# ESP32-H2 register map
Vendor: ESPRESSIF SYSTEMS (SHANGHAI) CO., LTD.; Series: ESP32 H-Series; File version: 12
CPU: RV32IMAC r0p0, little endian, no MPU, no FPU, 0 interrupt priority bits
Address unit: 32 bits
Registers are 32-bit, read-write, reset 0x0 unless marked. A register's access mark holds for its fields unless they carry their own. Offsets are from the block's base; [hi:lo] are bit positions; {n}, {i} and the like mark numbered series.

## HP_APM — HP_APM Peripheral
Base 0x60099000
0x00 REGION_FILTER_EN reset 0x1 — Region filter enable register
  [15:0] REGION_FILTER_EN — Region filter enable
{0x4+0xC*i} REGION{i}_ADDR_START (i=0..15) — Region address register
  [31:0] REGION{i}_ADDR_START — Start address of region{i}
{0x8+0xC*i} REGION{i}_ADDR_END reset 0xFFFFFFFF (i=0..15) — Region address register
  [31:0] REGION{i}_ADDR_END — End address of region{i}
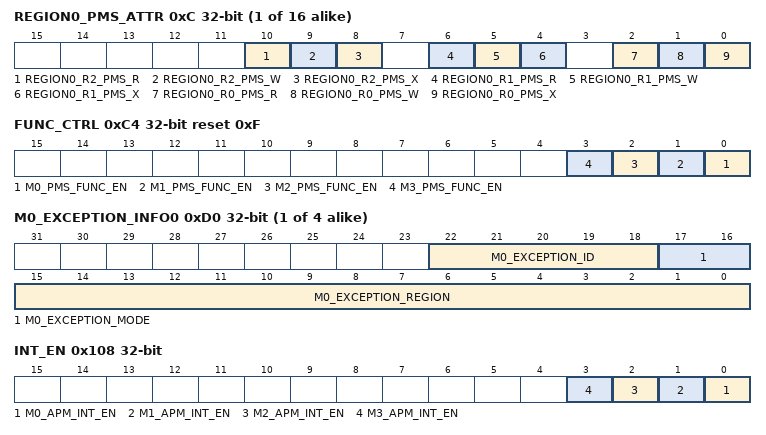
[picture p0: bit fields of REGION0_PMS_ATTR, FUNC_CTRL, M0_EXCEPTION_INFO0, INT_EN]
{0xC+0xC*i} REGION{i}_PMS_ATTR (i=0..15) — Region access authority attribute register
  [10] REGION{i}_R2_PMS_R — Region read authority in REE_MODE2
  [9] REGION{i}_R2_PMS_W — Region write authority in REE_MODE2
  [8] REGION{i}_R2_PMS_X — Region execute authority in REE_MODE2
  [6] REGION{i}_R1_PMS_R — Region read authority in REE_MODE1
  [5] REGION{i}_R1_PMS_W — Region write authority in REE_MODE1
  [4] REGION{i}_R1_PMS_X — Region execute authority in REE_MODE1
  [2] REGION{i}_R0_PMS_R — Region read authority in REE_MODE0
  [1] REGION{i}_R0_PMS_W — Region write authority in REE_MODE0
  [0] REGION{i}_R0_PMS_X — Region execute authority in REE_MODE0
0xC4 FUNC_CTRL reset 0xF — PMS function control register
  [n] M{n}_PMS_FUNC_EN (n=0..3) — PMS M{n} function enable
{0xC8+0x10*i} M{i}_STATUS ro (i=0..3)
  [1:0] M{i}_EXCEPTION_STATUS — Exception status
{0xCC+0x10*i} M{i}_STATUS_CLR wo (i=0..3) — M{i} status clear register
  [0] M{i}_REGION_STATUS_CLR — Clear exception status
{0xD0+0x10*i} M{i}_EXCEPTION_INFO0 ro (i=0..3)
  [22:18] M{i}_EXCEPTION_ID — Exception id information
  [17:16] M{i}_EXCEPTION_MODE — Exception mode
  [15:0] M{i}_EXCEPTION_REGION — Exception region
{0xD4+0x10*i} M{i}_EXCEPTION_INFO1 ro (i=0..3)
  [31:0] M{i}_EXCEPTION_ADDR — Exception addr
0x108 INT_EN — APM interrupt enable register
  [n] M{n}_APM_INT_EN (n=0..3) — APM M{n} interrupt enable
0x10C CLOCK_GATE reset 0x1 — clock gating register
  [0] CLK_EN — reg_clk_en
0x7FC DATE reset 0x2205240 — Version register
  [27:0] DATE — reg_date

## INTPRI — INTPRI Peripheral
Base 0x600C5000
0x00 CPU_INT_ENABLE — register description
  [31:0] CPU_INT_ENABLE — Need add description
0x04 CPU_INT_TYPE — register description
  [31:0] CPU_INT_TYPE — Need add description
0x08 CPU_INT_EIP_STATUS ro — register description
  [31:0] CPU_INT_EIP_STATUS — Need add description
{0xC+4i} CPU_INT_PRI_{i} (i=0..31) — register description
  [3:0] CPU_PRI_{i}_MAP — Need add description
0x8C CPU_INT_THRESH — register description
  [7:0] CPU_INT_THRESH — Need add description
{0x90+4i} CPU_INTR_FROM_CPU_{i} (i=0..3) — register description
  [0] CPU_INTR_FROM_CPU_{i} — Need add description
0xA0 DATE reset 0x2201090 — register description
  [27:0] DATE — Need add description
0xA4 CLOCK_GATE reset 0x1 — register description
  [0] CLK_EN — Need add description
0xA8 CPU_INT_CLEAR — register description
  [31:0] CPU_INT_CLEAR — Need add description
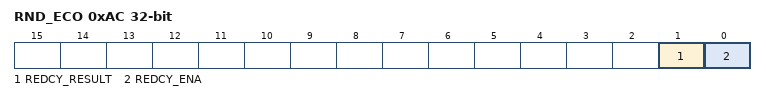
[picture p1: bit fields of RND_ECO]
0xAC RND_ECO access per field — redcy eco register.
  [1] REDCY_RESULT ro — Only reserved for ECO.
  [0] REDCY_ENA rw — Only reserved for ECO.
0xB0 RND_ECO_LOW — redcy eco low register.
  [31:0] REDCY_LOW — Only reserved for ECO.
0x3FC RND_ECO_HIGH reset 0xFFFFFFFF — redcy eco high register.
  [31:0] REDCY_HIGH — Only reserved for ECO.

## IO_MUX — Input/Output Multiplexer
Base 0x60090000
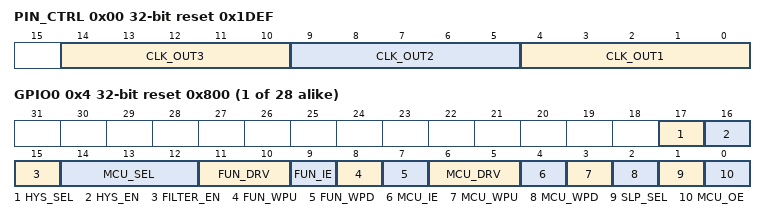
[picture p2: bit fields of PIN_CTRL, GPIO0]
0x00 PIN_CTRL reset 0x1DEF — Clock Output Configuration Register
  [14:10] CLK_OUT3 — If you want to output clock for I2S to CLK_OUT_out3, set this register to 0x0. CLK_OUT_out3 can be found in peripheral output signals.
  [9:5] CLK_OUT2 — If you want to output clock for I2S to CLK_OUT_out2, set this register to 0x0. CLK_OUT_out2 can be found in peripheral output signals.
  [4:0] CLK_OUT1 — If you want to output clock for I2S to CLK_OUT_out1, set this register to 0x0. CLK_OUT_out1 can be found in peripheral output signals.
{0x4+4i} GPIO{i} (i=0..27) reset 0x800 — IO MUX Configure Register for pad GPIO0
  [17] HYS_SEL — Select enabling signals of the pad from software and efuse hardware. 1: Select enabling siganl from slftware. 0: Select enabling signal from efuse hardware.
  [16] HYS_EN — Software enables hysteresis function for the pad. 1: Hysteresis enabled. 0: Hysteresis disabled.
  [15] FILTER_EN — Enable filter for pin input signals. 1: Filter enabled. 0: Filter disabled.
  [14:12] MCU_SEL — Select IO MUX function for this signal. 0: Select Function 1. 1: Select Function 2. etc.
  [11:10] FUN_DRV — Select the drive strength of the pad. 0: ~5 mA. 1: ~10mA. 2: ~20mA. 3: ~40mA.
  [9] FUN_IE — Input enable of the pad. 1: input enabled. 0: input disabled.
  [8] FUN_WPU — Pull-up enable of the pad. 1: internal pull-up enabled. 0: internal pull-up disabled.
  [7] FUN_WPD — Pull-down enable of the pad. 1: internal pull-down enabled. 0: internal pull-down disabled.
  [6:5] MCU_DRV — Select the drive strength of the pad during sleep mode. 0: ~5 mA. 1: ~10mA. 2: ~20mA. 3: ~40mA.
  [4] MCU_IE — Input enable of the pad during sleep mode. 1: input enabled. 0: input disabled.
  [3] MCU_WPU — Pull-up enable of the pad during sleep mode. 1: internal pull-up enabled. 0: internal pull-up disabled.
  [2] MCU_WPD — Pull-down enable of the pad in sleep mode. 1: internal pull-down enabled. 0: internal pull-down disabled.
  [1] SLP_SEL — Sleep mode selection of this pad. Set to 1 to put the pad in pad mode.
  [0] MCU_OE — Output enable of the pad in sleep mode. 1: output enabled. 0: output disabled.
0xBC MODEM_DIAG_EN — GPIO MATRIX Configure Register for modem diag
  [31:0] MODEM_DIAG_EN — bit i to enable modem_diag[i] into gpio matrix. 1:enable modem_diag[i] into gpio matrix. 0:enable other signals into gpio matrix
0xFC DATE reset 0x2207270 — IO MUX Version Control Register
  [27:0] REG_DATE — Version control register
